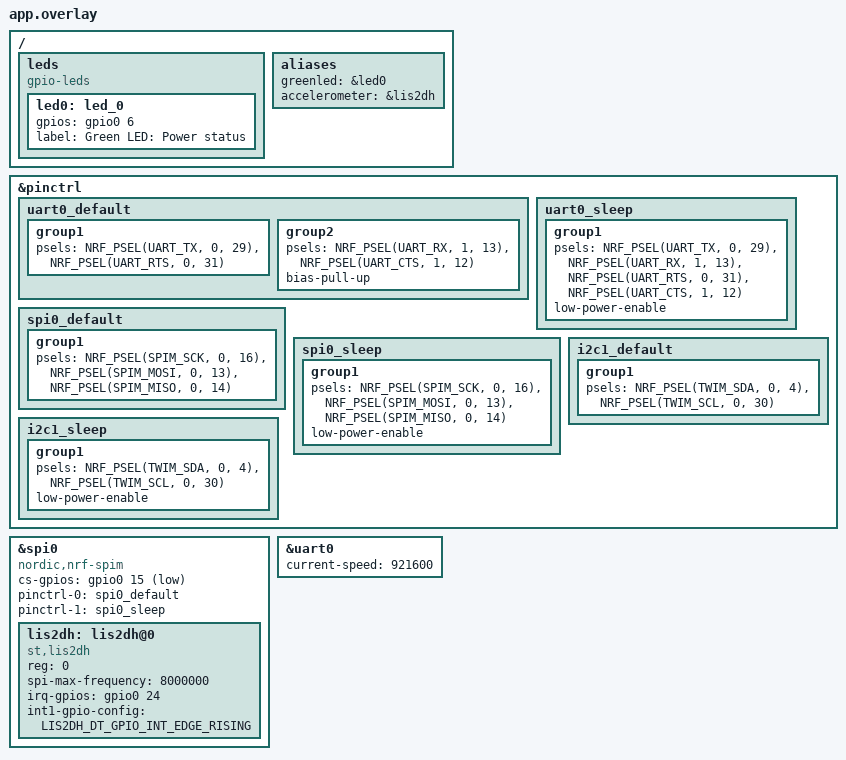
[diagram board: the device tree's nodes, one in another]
 #include <zephyr/dt-bindings/sensor/lis2dh.h>
 #include <zephyr/dt-bindings/sensor/stts22h.h>

 / {
	leds {
		compatible = "gpio-leds";
		status = "okay";
		led0: led_0 {
			gpios = <&gpio0 6 (GPIO_ACTIVE_HIGH | GPIO_PULL_DOWN)>;
			label = "Green LED: Power status";
			status = "okay";
		};
		// led1: led_1 {
		// 	gpios = <&gpio0 14 (GPIO_ACTIVE_LOW | GPIO_PULL_DOWN)>;
		// 	label = "Orange LED: TX status";
		// 	status = "disabled";
		// };
		// led2: led_2 {
		// 	gpios = <&gpio0 13 (GPIO_ACTIVE_LOW | GPIO_PULL_DOWN)>;
		// 	label = "Red LED: RX status";
		// 	status = "disabled";
		// };
		// led3: led_3 {
		// 	gpios = <&gpio0 19 (GPIO_ACTIVE_LOW | GPIO_PULL_DOWN)>;
		// 	label = "Yellow LED: BLE connection status";
		// 	status = "disabled";
		// };
		// led4: led_4 {
		// 	gpios = < &gpio0 17 (GPIO_ACTIVE_LOW | GPIO_PULL_DOWN)>;
		// 	label = "Blue LED: BLE status";
		// 	status = "disabled";
		// };
	};

	// buttons {
	// 	compatible = "gpio-keys";
	// 	status = "disabled";
	// 	button0: button_0 {
	// 		gpios = <&gpio0 24 (GPIO_PULL_UP | GPIO_ACTIVE_HIGH)>;
	// 		label = "INT1 pin testing";
	// 		zephyr,code = <INPUT_KEY_0>;
	// 	};
	// 	button1: button_1 {
	// 		gpios = <&gpio0 12 (GPIO_PULL_UP | GPIO_ACTIVE_HIGH)>;
	// 		label = "Rotary switch: 0";
	// 		status = "disabled";
	// 	};
	// 	button2: button_2 {
	// 		gpios = <&gpio0 27 (GPIO_PULL_UP | GPIO_ACTIVE_HIGH)>;
	// 		label = "Rotary switch: 1";
	// 		status = "disabled";
	// 	};
	// 	button3: button_3 {
	// 		gpios = <&gpio0 7 (GPIO_PULL_UP | GPIO_ACTIVE_HIGH)>;
	// 		label = "Rotary switch: 2";
	// 		status = "disabled";
	// 	};
	// 	button4: button_4 {
	// 		gpios = <&gpio0 6 (GPIO_PULL_UP | GPIO_ACTIVE_HIGH)>;
	// 		label = "Rotary switch: 4 Unsupported pin";
	// 		status = "disabled";
	// 	};
	// };

	aliases {
		greenled = &led0;
		accelerometer = &lis2dh;
	};
};

&pinctrl {
	uart0_default: uart0_default {
		group1 {
			psels = <NRF_PSEL(UART_TX, 0, 29)>,
					<NRF_PSEL(UART_RTS, 0, 31)>;
			};
		group2 {
			psels = <NRF_PSEL(UART_RX, 1, 13)>,
					<NRF_PSEL(UART_CTS, 1, 12)>;
					bias-pull-up;
			};
	};

	uart0_sleep: uart0_sleep {
		group1 {
			psels = <NRF_PSEL(UART_TX, 0, 29)>,
					<NRF_PSEL(UART_RX, 1, 13)>,
					<NRF_PSEL(UART_RTS, 0, 31)>,
					<NRF_PSEL(UART_CTS, 1, 12)>;
					low-power-enable;
		};
	};

	spi0_default: spi0_default {
		group1 {
			psels = <NRF_PSEL(SPIM_SCK, 0, 16)>,
				<NRF_PSEL(SPIM_MOSI, 0, 13)>,
				<NRF_PSEL(SPIM_MISO, 0, 14)>;
		};
	};

	spi0_sleep: spi0_sleep {
		group1 {
			psels = <NRF_PSEL(SPIM_SCK, 0, 16)>,
				<NRF_PSEL(SPIM_MOSI, 0, 13)>,
				<NRF_PSEL(SPIM_MISO, 0, 14)>;
			low-power-enable;
		};
	};

	i2c1_default: i2c1_default {
		group1 {
			psels = <NRF_PSEL(TWIM_SDA, 0, 4)>,
				<NRF_PSEL(TWIM_SCL, 0, 30)>;
		};
	};

	i2c1_sleep: i2c1_sleep {
		group1 {
			psels = <NRF_PSEL(TWIM_SDA, 0, 4)>,
				<NRF_PSEL(TWIM_SCL, 0, 30)>;
			low-power-enable;
		};
	};
};

&spi0 {
	status = "okay";
	compatible = "nordic,nrf-spim";
	cs-gpios = <&gpio0 15 GPIO_ACTIVE_LOW>;
	pinctrl-0 = <&spi0_default>;
	pinctrl-1 = <&spi0_sleep>;
	pinctrl-names = "default", "sleep";
	// zephyr,pm-device-runtime-auto;

	lis2dh: lis2dh@0 {
		compatible = "st,lis2dh";
		reg = <0>;
		spi-max-frequency = <8000000>;
		irq-gpios = <&gpio0 24 (GPIO_ACTIVE_HIGH)>; // GPIO_PULL_DOWN
		int1-gpio-config = <LIS2DH_DT_GPIO_INT_EDGE_RISING>;
		status = "okay";
	};
};

&uart0 {
	current-speed = <921600>;
	status = "okay";
};
